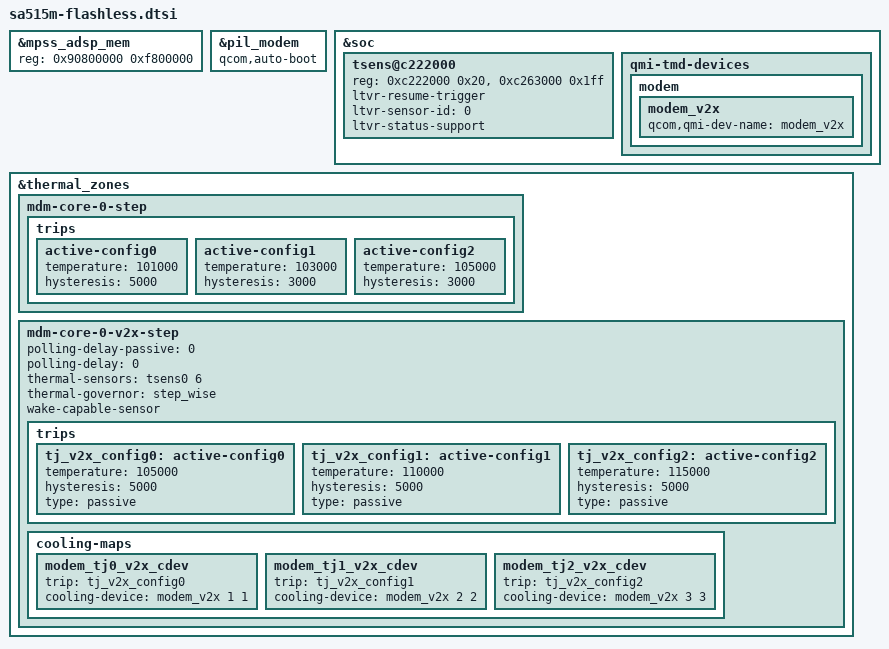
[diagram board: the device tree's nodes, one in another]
/* Copyright (c) 2019-2021, The Linux Foundation. All rights reserved.
 *
 * This program is free software; you can redistribute it and/or modify
 * it under the terms of the GNU General Public License version 2 and
 * only version 2 as published by the Free Software Foundation.
 *
 * This program is distributed in the hope that it will be useful,
 * but WITHOUT ANY WARRANTY; without even the implied warranty of
 * MERCHANTABILITY or FITNESS FOR A PARTICULAR PURPOSE.  See the
 * GNU General Public License for more details.
 */

#include "sdxprairie.dtsi"

&mpss_adsp_mem {
	reg = <0x90800000 0xf800000>;
};

&pil_modem {
	qcom,auto-boot;
};

&soc {
	tsens@c222000 {
		reg = <0xc222000 0x20>,
			<0xc263000 0x1ff>;
		ltvr-resume-trigger;
		ltvr-sensor-id = <0>;
		ltvr-status-support;
	};

	qmi-tmd-devices {
		modem {
			modem_v2x: modem_v2x {
				qcom,qmi-dev-name = "modem_v2x";
				#cooling-cells = <2>;
			};
		};
	};
};

&thermal_zones {
	/delete-node/ aoss0-usr;
	/delete-node/ mdm-q6-lowf;
	/delete-node/ ipa-lowf;
	/delete-node/ cpu0-0-lowf;
	/delete-node/ mdm-core-2-lowf;
	/delete-node/ mdm-core-1-lowf;
	/delete-node/ mdm-core-0-lowf;
	/* update Tj thresholds */
	mdm-core-0-step {
		trips {
			active-config0 {
				temperature = <101000>;
				hysteresis = <5000>;
			};

			active-config1 {
				temperature = <103000>;
				hysteresis = <3000>;
			};

			active-config2 {
				temperature = <105000>;
				hysteresis = <3000>;
			};
		};
	};

	mdm-core-0-v2x-step {
		polling-delay-passive = <0>;
		polling-delay = <0>;
		thermal-sensors = <&tsens0 6>;
		thermal-governor = "step_wise";
		wake-capable-sensor;

		trips {
			tj_v2x_config0: active-config0 {
				temperature = <105000>;
				hysteresis = <5000>;
				type = "passive";
			};

			tj_v2x_config1: active-config1 {
				temperature = <110000>;
				hysteresis = <5000>;
				type = "passive";
			};

			tj_v2x_config2: active-config2 {
				temperature = <115000>;
				hysteresis = <5000>;
				type = "passive";
			};
		};

		cooling-maps {
			modem_tj0_v2x_cdev {
				trip = <&tj_v2x_config0>;
				cooling-device = <&modem_v2x 1 1>;
			};

			modem_tj1_v2x_cdev {
				trip = <&tj_v2x_config1>;
				cooling-device = <&modem_v2x 2 2>;
			};

			modem_tj2_v2x_cdev {
				trip = <&tj_v2x_config2>;
				cooling-device = <&modem_v2x 3 3>;
			};
		};
	};
};
